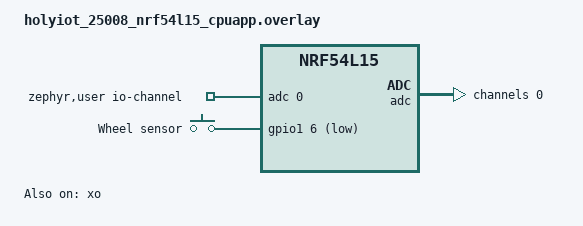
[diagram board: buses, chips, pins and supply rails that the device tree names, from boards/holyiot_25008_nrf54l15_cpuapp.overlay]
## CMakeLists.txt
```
# SPDX-License-Identifier: Apache-2.0

cmake_minimum_required(VERSION 3.20.0)

# Application-specific Kconfig options (CSC service, wheel simulation).
set(KCONFIG_ROOT ${CMAKE_CURRENT_SOURCE_DIR}/Kconfig)

find_package(Zephyr REQUIRED HINTS $ENV{ZEPHYR_BASE})
project(speed_meter)

target_sources(app PRIVATE
	src/main.c
	src/csc.c
	src/bt.c
	src/led_sw_blink.c
)

# Wheel configuration (circumference, ODR, range, detector thresholds) with
# persistence in NVS. Used by every wheel source and by the diagnostics shell.
target_sources(app PRIVATE src/wheel_config.c)

# CSCS wire state: the event-time clock and the cumulative revolution counter.
# Free of Zephyr dependencies so it can be unit-tested on the host.
target_sources(app PRIVATE src/wheel_csc.c)

# Fail-closed gate for sensor reconfiguration. Same reasoning.
target_sources(app PRIVATE src/wheel_reconfig.c)

# CR2032 measurement through the SAADC internal VDD input + Battery Service.
target_sources_ifdef(CONFIG_CSC_BATTERY app PRIVATE src/battery.c)

# Wheel revolution sources - `choice CSC_WHEEL_SOURCE` builds exactly one.
target_sources_ifdef(CONFIG_CSC_SIMULATE app PRIVATE src/wheel_source_sim.c)
target_sources_ifdef(CONFIG_CSC_WHEEL_SENSOR_GPIO app PRIVATE src/wheel_source_gpio.c)
target_sources_ifdef(CONFIG_CSC_WHEEL_SENSOR_ACCEL app PRIVATE src/wheel_source_accel.c)

# Self-calibrating revolution detector (accelerometer source and/or recorder).
target_sources_ifdef(CONFIG_CSC_WHEEL_DETECTOR app PRIVATE src/wheel_detector.c)

# Remote diagnostics (recording + calibration over the MCUmgr/SMP shell).
target_sources_ifdef(CONFIG_CSC_DIAG app PRIVATE src/wheel_diag.c)

# Low-power management (sleep on wheel standstill, wake on motion).
target_sources_ifdef(CONFIG_CSC_POWER_SAVE app PRIVATE src/wheel_power.c)

# On-demand firmware update (DFU) over BLE SMP.
target_sources_ifdef(CONFIG_CSC_DFU app PRIVATE src/dfu_mode.c)
target_sources_ifdef(CONFIG_CSC_DFU app PRIVATE src/dfu_button.c)

# Boot self-test and firmware confirmation (MCUboot).
target_sources_ifdef(CONFIG_BOOTLOADER_MCUBOOT app PRIVATE src/boot.c)
```

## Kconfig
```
# SPDX-License-Identifier: Apache-2.0

menu "Speed Meter application"

config CSC_WHEEL_REV_DATA
	bool "Wheel revolution data (speed)"
	default y
	help
	  Expose wheel revolution data: CSC Feature bit 0 and wheel fields in
	  every CSC Measurement notification. Required for speed readings.

config CSC_CRANK_REV_DATA
	bool "Crank revolution data (cadence)"
	default n
	help
	  Expose crank revolution data: CSC Feature bit 1 and crank fields in
	  every CSC Measurement notification.

config CSC_SENSOR_LOCATION
	int "Sensor Location characteristic value (0x2A5D)"
	default 9
	range 0 14
	help
	  Sensor location as defined by the Bluetooth SIG:
	  0=Other, 1=Top of shoe, 2=In shoe, 3=Hip, 4=Front wheel,
	  5=Left crank, 6=Right crank, 7=Left pedal, 8=Right pedal,
	  9=Front hub, 10=Rear dropout, 11=Chainstay, 12=Rear wheel,
	  13=Rear hub, 14=Chest.

config CSC_SC_CONTROL_POINT
	bool "SC Control Point characteristic (calibration, sensor location)"
	default n
	help
	  Expose the optional SC Control Point (0x2A55) with SET CUMULATIVE
	  VALUE, UPDATE SENSOR LOCATION and REQUEST SUPPORTED SENSOR
	  LOCATIONS opcodes (CSCS v1.0). Ported from the upstream
	  peripheral_csc sample - see reference/README.md.

config CSC_BATTERY
	bool "CR2032 voltage measurement through the SAADC VDD input"
	default y
	depends on ADC
	help
	  Measure the coin cell through the nRF54L15 SAADC's internal VDD input:
	  no divider, no extra pin, nothing to solder (the channel lives in the
	  board overlay as the first io-channel of the zephyr,user node).

	  The voltage is published as a percentage through the standard BLE
	  Battery Service. Turn this off to fall back to the fixed
	  CSC_BAS_LEVEL instead, e.g. when the board is powered from a bench
	  supply.

config CSC_BATTERY_INTERVAL_RIDING_S
	int "Battery measurement interval while riding (seconds)"
	default 300
	range 10 3600
	depends on CSC_BATTERY
	help
	  A coin cell sags under load, so the level is sampled more often while
	  the wheel is turning and the radio is busy.

config CSC_BATTERY_INTERVAL_IDLE_S
	int "Battery measurement interval while parked (seconds)"
	default 3600
	range 60 86400
	depends on CSC_BATTERY
	help
	  Relaxed cadence for a device sitting still; the measurement itself is
	  what costs power, not the timer.

config CSC_BATTERY_CAL_PPM
	int "Battery voltage calibration (parts per million)"
	default 0
	range -200000 200000
	depends on CSC_BATTERY
	help
	  Single trim factor for the measured voltage. The SAADC is accurate but
	  not exact, so compare the reported millivolts against a multimeter and
	  set the relative error here: -30000 corrects a reading that is 3% too
	  high. Watch out that a J-Link supplying the board makes the SAADC
	  measure the debugger's rail, not the cell.

config CSC_BAS_LEVEL
	int "Battery level reported when measurement is off (percent)"
	default 100
	range 0 100
	depends on BT_BAS
	help
	  Fallback published by the Battery Service (0x180F) when
	  CONFIG_CSC_BATTERY is disabled. With measurement enabled this value is
	  never used - the level comes from the SAADC.

choice CSC_WHEEL_SOURCE
	prompt "Wheel revolution source"
	default CSC_SIMULATE
	depends on CSC_WHEEL_REV_DATA
	help
	  Where wheel revolution data comes from.

config CSC_SIMULATE
	bool "Simulated wheel revolutions"
	help
	  Generate fake wheel revolutions so the sensor can be paired and
	  tested with Apple Watch / a phone before the real wheel sensor
	  hardware is attached.

config CSC_WHEEL_SENSOR_GPIO
	bool "Wheel sensor on GPIO (pulse input, alias 'wheel-sensor')"
	help
	  Count wheel revolutions from a pulse input on a GPIO - e.g. a Hall
	  sensor or a magnetic pulse contact. The pin comes from the
	  'wheel-sensor' devicetree alias (see the board overlay) and must be
	  on a port with GPIOTE support - P0 or P1 on nRF54L15, P2 has none.

config CSC_WHEEL_SENSOR_ACCEL
	bool "Magnetless: revolutions from the accelerometer (LIS2DH)"
	select SENSOR
	select LIS2DH
	select CSC_WHEEL_DETECTOR
	help
	  Count wheel revolutions from the gravity rotation the accelerometer
	  sees - no magnet and no Hall sensor on the wheel. The detector is
	  self-calibrating: the rotation plane, the axis signs and the
	  sensor-to-axis distance are all derived from the data, so the board
	  may be mounted in any orientation. Add power.conf to get automatic
	  sleep on standstill and wake on movement. The sensor comes from the
	  devicetree alias 'accel0'.

endchoice

config CSC_WHEEL_DETECTOR
	bool
	help
	  Internal: build the self-calibrating revolution detector. Selected by
	  the accelerometer wheel source and by the diagnostics recorder, both
	  of which feed it. Not user selectable.

config CSC_WHEEL_SENSOR_DEBOUNCE_MS
	int "Wheel sensor debounce time in milliseconds"
	default 20
	range 1 200
	depends on CSC_WHEEL_SENSOR_GPIO

config CSC_SIM_WHEEL_RPS
	int "Simulated wheel revolutions per second"
	default 1
	range 1 20
	depends on CSC_SIMULATE

config CSC_SIMULATE_CRANK
	bool "Simulate crank revolutions"
	default y
	depends on CSC_CRANK_REV_DATA && CSC_SIMULATE
	help
	  Generate fake crank revolutions (cadence).

config CSC_SIM_CRANK_RPM
	int "Simulated crank revolutions per minute"
	default 60
	range 20 180
	depends on CSC_SIMULATE_CRANK

config CSC_SIM_TICK_MS
	int "Simulation tick period in milliseconds"
	default 100
	range 10 1000
	depends on CSC_SIMULATE

config CSC_DIAG
	bool "Remote diagnostics: accelerometer recording and calibration"
	default n
	depends on SENSOR && SHELL
	select CSC_WHEEL_DETECTOR
	help
	  Shell commands for remote measurements over MCUmgr/SMP (used by
	  tools/wheel_cal.py): wheel status, cal get/set and accelerometer
	  recording (record start/stop/info/dump). Enable together with
	  diag.conf.

config CSC_DIAG_REC_SAMPLES
	int "Wheel diagnostics recording buffer size (samples)"
	default 4096
	range 256 16384
	depends on CSC_DIAG

config CSC_POWER_SAVE
	bool "Low-power mode: sleep on wheel standstill"
	default n
	depends on SPI
	help
	  Puts the LIS2DH12 into a 1 Hz low-power mode with a movement interrupt
	  armed on the selected INT line whenever the wheel stops, and stops the
	  BLE links and the advertising once the ride is over.

	  There is no System OFF tier: waking from it needs GPIO DETECT on P0/P1,
	  and this board's accelerometer interrupts sit on port P2, which has no
	  gpiote instance. wheel_power.c explains it at the point of use.

choice CSC_POWER_WAKE_INT
	prompt "Interrupt line the sensor arms on standstill"
	default CSC_POWER_WAKE_INT1
	depends on CSC_POWER_SAVE
	help
	  Which INT pin the LIS2DH12 routes its movement interrupt to while
	  standing still. On HOLYIOT-25008 nothing on the SoC reads either line -
	  both are on port P2, which has no GPIOTE - so this only sets what the
	  sensor does, and the 1 Hz poll is what actually notices movement.
	  Kept because it is what a board with a readable line would need.

config CSC_POWER_WAKE_INT1
	bool "INT1"

config CSC_POWER_WAKE_INT2
	bool "INT2"

endchoice

config CSC_POWER_IDLE_TIMEOUT_S
	int "Standstill timeout before sleeping (seconds)"
	default 10
	range 2 300
	depends on CSC_POWER_SAVE
	help
	  Tier 2 of the power state machine: after this long without a wheel
	  revolution the sensor alone drops to 1 Hz with a movement interrupt.
	  The BLE link is kept - stopping at a traffic light must not cost the
	  rider their connection - and the CPU stays idle between connection
	  events, which is where the saving is.

config CSC_POWER_DEEP_SLEEP_TIMEOUT_S
	int "Standstill timeout before the ride is considered over (seconds)"
	default 300
	range 30 3600
	depends on CSC_POWER_SAVE
	help
	  Tier 3: after this long without a revolution the ride is over. The BLE
	  links are dropped, the advertising stops, and the device settles into
	  System ON Idle. The first wheel movement brings everything back - the
	  sampling thread polls once a second and is its own wake source.

	  It must stay well above the traffic-light scale - the default of 5
	  minutes is the behaviour of the commercial speed sensors.

config CSC_POWER_WAKE_THS
	int "Wake threshold (INTx_THS, in +/-2g digits)"
	default 16
	range 1 127
	depends on CSC_POWER_SAVE
	help
	  Each digit is 16 mg at the standby full scale (+/-2 g). 16 digits means
	  a ~256 mg movement wakes the device.

config CSC_DFU
	bool "On-demand firmware update (DFU) over BLE"
	default n
	depends on MCUMGR_TRANSPORT_BT_DYNAMIC_SVC_REGISTRATION && MCUMGR_GRP_IMG
	help
	  Hides the MCUmgr/SMP service until dfu_mode_enter() is called (e.g. by
	  a long button press). The device then advertises as "Wheel DFU" and a
	  phone uploads a signed image to the second slot; MCUboot installs it on
	  the next reboot. Enable together with dfu.conf.

config CSC_DFU_BUTTON_LONG_MS
	int "DFU button hold duration (milliseconds)"
	default 5000
	range 1000 10000
	depends on CSC_DFU

endmenu

source "Kconfig.zephyr"
```

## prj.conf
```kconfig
# SPDX-License-Identifier: Apache-2.0
#
# Speed Meter - Bluetooth cycling speed sensor (CSCS).

# --- Bluetooth: peripheral with the Cycling Speed and Cadence service --------
CONFIG_BT=y
CONFIG_BT_PERIPHERAL=y
CONFIG_BT_DEVICE_NAME="Speed Meter"
# "Cycling: General" style appearance used by cycling sensors.
CONFIG_BT_DEVICE_APPEARANCE=1157

# Two simultaneous centrals: the Apple Watch plus a bike computer / phone
# display, both subscribed to CSC Measurement at the same time. The service
# is only advertised while fewer than BT_MAX_CONN links are up (see bt.c).
CONFIG_BT_MAX_CONN=2
CONFIG_BT_MAX_PAIRED=2
# Both Apple clients keep their own bond, and reconnecting relies on them.
CONFIG_BT_SMP=y
CONFIG_BT_SETTINGS=y

# --- Persistent configuration ------------------------------------------------
# Settings + NVS on the RRAM "storage" partition (0x174000, 36 kB):
#   - Bluetooth bonds (BT_SETTINGS) so paired watch/display reconnect after a
#     reboot or a battery change without re-pairing,
#   - wheel configuration (circumference, ODR, range, detector thresholds),
#     see src/wheel_config.c.
#
# FLASH is off by default unless MCUboot is part of the build, so ask for the
# Nordic RRAM driver explicitly; SETTINGS_NVS additionally needs FLASH_MAP.
CONFIG_FLASH=y
CONFIG_FLASH_MAP=y
CONFIG_NVS=y
CONFIG_SETTINGS=y
CONFIG_SETTINGS_NVS=y

# The CSCS service UUID (0x1816) is put in the advertising data by
# src/main.c - that is what Apple Watch scans for.

# Battery Service and Device Information Service (nice for Apple clients).
# The level comes from the SAADC; see the battery section below.
CONFIG_BT_BAS=y
CONFIG_BT_DIS=y
CONFIG_BT_DIS_PNP=n

# --- CR2032 measurement (SAADC internal VDD input) ---------------------------
# The CR2032 feeds VDD, so the SAADC can measure it internally: no divider, no
# extra pin, nothing to solder. The channel is configured in the board overlay
# as the first io-channel of the zephyr,user node - check it before changing
# anything here. CONFIG_CSC_BATTERY (Kconfig) controls the module itself.
CONFIG_ADC=y

# --- Logging -----------------------------------------------------------------
CONFIG_LOG=y
CONFIG_LOG_DEFAULT_LEVEL=3

# --- LED (Zephyr LED driver over the board's gpio-leds node) -----------------
CONFIG_LED=y

# --- Console over J-Link RTT -------------------------------------------------
# UART (P1.04 TX / P1.05 RX) is repurposed: P1.05 carries the LIS2DH12 INT1
# wake line. Keep the UART console off and log over RTT instead.
CONFIG_UART_CONSOLE=n
CONFIG_LOG_BACKEND_UART=n
CONFIG_RTT_CONSOLE=y
CONFIG_USE_SEGGER_RTT=y
CONFIG_LOG_BACKEND_RTT=y
CONFIG_LOG_BACKEND_RTT_MODE_DROP=y
```

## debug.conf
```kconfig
# SPDX-License-Identifier: Apache-2.0
#
# Extra configuration for bench debugging.
#
# NOTE: logging over J-Link RTT and the disabled UART console are now part of
# prj.conf (they apply to every build). This file is kept for build-command
# compatibility only - add any debug-only settings here.
```

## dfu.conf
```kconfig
# SPDX-License-Identifier: Apache-2.0
#
# On-demand firmware update (DFU) over BLE SMP via MCUboot.
#
# Usage (sysbuild builds MCUboot + app and merges them):
#   west build --sysbuild -b holyiot_25008/nrf54l15/cpuapp . -- \
#       -DEXTRA_CONF_FILE="debug.conf;diag.conf;power.conf;dfu.conf"
#
# The signed image to upload from nRF Connect Device Manager is:
#   build/speed_meter_diag_power_mcuboot/app/zephyr/zephyr.signed.bin

# Application-side DFU support (dfu_mode.c + dfu_button.c).
CONFIG_CSC_DFU=y

# MCUboot image management (upload + confirm + reset).
CONFIG_BOOTLOADER_MCUBOOT=y
CONFIG_FLASH=y
CONFIG_FLASH_MAP=y
CONFIG_STREAM_FLASH=y
CONFIG_IMG_MANAGER=y

# MCUmgr image-management group (in addition to the OS/shell groups from
# diag.conf).
CONFIG_MCUMGR_GRP_IMG=y

# Enable MCUmgr notification hooks (img_mgmt callbacks drive the DFU LED
# states: upload in progress / image received).
CONFIG_MCUMGR_MGMT_NOTIFICATION_HOOKS=y

# Security: pairing/encryption for the SMP service.
CONFIG_BT_SMP=y
CONFIG_BT_GATT_DYNAMIC_DB=y

# Register the SMP service on demand only (hidden until DFU mode is entered).
CONFIG_MCUMGR_TRANSPORT_BT_DYNAMIC_SVC_REGISTRATION=y
CONFIG_MCUMGR_TRANSPORT_BT_CONN_PARAM_CONTROL=y

# Require an encrypted link (overrides the plain bench permission from
# diag.conf - the DFU build is production, the bench tool uses its own build).
CONFIG_MCUMGR_TRANSPORT_BT_PERM_RW=n
CONFIG_MCUMGR_TRANSPORT_BT_PERM_RW_ENCRYPT=y

# Faster transfers.
CONFIG_BT_L2CAP_TX_MTU=498
CONFIG_BT_BUF_ACL_RX_SIZE=502
CONFIG_BT_BUF_ACL_TX_SIZE=502
CONFIG_BT_CTLR_DATA_LENGTH_MAX=251

CONFIG_MCUMGR_TRANSPORT_BT_REASSEMBLY=y
CONFIG_MCUMGR_TRANSPORT_NETBUF_SIZE=2475
CONFIG_MCUMGR_TRANSPORT_WORKQUEUE_STACK_SIZE=4608
```

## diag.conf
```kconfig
# SPDX-License-Identifier: Apache-2.0
#
# Extra configuration for the remote diagnostics build: accelerometer
# recording + calibration over MCUmgr/SMP (used by tools/wheel_cal.py).
#
# Usage:
#   west build -b holyiot_25008/nrf54l15/cpuapp . -- \
#       -DEXTRA_CONF_FILE="debug.conf;diag.conf"

# --- wheel diagnostics module ------------------------------------------------
CONFIG_SENSOR=y
CONFIG_LIS2DH=y
CONFIG_CSC_DIAG=y
CONFIG_CSC_DIAG_REC_SAMPLES=4096

# --- shell over MCUmgr (no UART console needed) ------------------------------
CONFIG_SHELL=y
CONFIG_SHELL_BACKEND_DUMMY=y
CONFIG_SHELL_BACKEND_DUMMY_BUF_SIZE=2048

CONFIG_MCUMGR=y
# MCUmgr dependencies (bez nich CONFIG_MCUMGR cicho spada do =n!).
CONFIG_NET_BUF=y
CONFIG_ZCBOR=y
CONFIG_CRC=y
CONFIG_MCUMGR_GRP_OS=y
CONFIG_MCUMGR_GRP_SHELL=y
CONFIG_MCUMGR_TRANSPORT_BT=y
# smpmgr on macOS cannot do Secure Connections pairing -> plain RW (bench only!)
CONFIG_MCUMGR_TRANSPORT_BT_PERM_RW=y
CONFIG_MCUMGR_TRANSPORT_BT_REASSEMBLY=y
CONFIG_MCUMGR_TRANSPORT_NETBUF_SIZE=2475
CONFIG_MCUMGR_TRANSPORT_WORKQUEUE_STACK_SIZE=3072
```

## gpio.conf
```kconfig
# SPDX-License-Identifier: Apache-2.0
#
# Wheel revolutions from a GPIO pulse input (Hall sensor, reed contact or any
# switch to GND) instead of the accelerometer - see src/wheel_source_gpio.c.
# The pin comes from the `wheel-sensor` devicetree alias.
#
# Usage:
#   west build -b holyiot_25008/nrf54l15/cpuapp . -- \
#       -DEXTRA_CONF_FILE="debug.conf;gpio.conf"

CONFIG_CSC_SIMULATE=n
CONFIG_CSC_WHEEL_SENSOR_GPIO=y
```

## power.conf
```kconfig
# SPDX-License-Identifier: Apache-2.0
#
# Production power configuration. Wheel revolutions come from the accelerometer
# (magnetless) and the LIS2DH12 drops to a 1 Hz standby whenever the wheel
# stops.
#
# Usage:
#   west build --sysbuild -b holyiot_25008/nrf54l15/cpuapp . -- \
#       -DEXTRA_CONF_FILE="debug.conf;diag.conf;power.conf;dfu.conf"

# --- Wheel source: accelerometer, not the simulator ---------------------------
CONFIG_CSC_SIMULATE=n
CONFIG_CSC_WHEEL_SENSOR_ACCEL=y

# --- Standstill policy: three tiers, and no System OFF ------------------------
#
#   tier 2 (10 s)   the sensor alone drops to 1 Hz and the BLE link stays up -
#                   stopping at a traffic light must not cost the rider the
#                   watch connection.
#   tier 3 (300 s)  the ride is over: links dropped, advertising stopped, and
#                   the device settles into System ON Idle. The 1 Hz wheel poll
#                   is its own wake source, so the wheel still starts the
#                   device by itself with nothing pressed.
#
# There is no System OFF tier. That is not an oversight and not a TODO.
# Waking from System OFF is GPIO DETECT on P0/P1, or RESET - this part has no
# timer wake to fall back on - and the module wires the accelerometer's INT1
# and INT2 to P2.00 and P2.03, on a port that carries no gpiote-instance in the
# SoC devicetree (gpiote30 belongs to gpio0, gpiote20 to gpio1). An unmodified
# board therefore has no wake source at all, and arming one would power the
# device down and never bring it back. The board cannot usefully be modified.
#
# The cost is battery life, not function, and it is smaller than it sounds:
# advertising every 100 ms plus a maintained link runs to tens of microamps,
# while the core idling between two 1 Hz polls costs a few. Whether that gap is
# worth buying back is a measurement question, not an argument - section 8 of
# TEST-PLAN.md specifies it, and nothing has been measured yet.
CONFIG_CSC_POWER_SAVE=y
```

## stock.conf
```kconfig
# SPDX-License-Identifier: Apache-2.0
#
# Production variant for an UNMODIFIED HOLYIOT-25008: nothing soldered, nothing
# rewired. Flash this if you have not touched the board.
#
# What works: the magnetless accelerometer source, the revolution detector, the
# CSCS service, and the full three-tier power state machine - tier 2 drops the
# sensor to 1 Hz while keeping the BLE link, tier 3 stops the links and the
# advertising altogether.
#
# What cannot work: System OFF, and the difference matters. Waking from System
# OFF on nRF54L15 is GPIO DETECT on P0/P1, or RESET - there is no timer wake to
# fall back on. The module wires INT1 to P2.00, and port 2 has neither GPIOTE
# nor SENSE, so a board that has not been modified has no way to wake the SoC.
# Arming a wake pin that is not connected would power the device down for good,
# so this variant does not arm one - and Kconfig refuses the option without
# CSC_POWER_WAKE_LINE_WIRED.
#
# Tier 3 therefore sleeps the radio instead of the chip. The device stays in
# **System ON Idle**: the links are dropped, the advertising stops, the sensor
# runs at 1 Hz, and the CPU stops in WFI between the once-a-second polls while
# everything else - RAM, LFCLK, the GRTC - keeps running. The sampling thread is
# what notices the wheel turning again and restarts advertising, so the wheel
# still starts the device by itself.
#
# System ON Idle is a description, not a switch that gets turned on. On
# nRF54L15 it is what arch_cpu_idle() does - __WFI() - and the only knob nearby
# is CONFIG_SOC_NRF_FORCE_CONSTLAT, left off because it trades power for wake
# latency.
#
# CONFIG_PM is a dead end here. This SoC selects no HAS_PM and implements no
# pm_state_set() - only nrf54h and nrf92 do - so CONFIG_PM=y does not take:
# Kconfig reports that PM "was assigned the value 'y' but got the value 'n'",
# the build still succeeds with exit 0, and the resulting .config has PM=n.
# Nothing breaks, and nothing happens either.
#
# The cost is battery life, not function, and it is smaller than it sounds:
# advertising every 100 ms plus a maintained link runs to tens of microamps,
# while the core idling between two 1 Hz polls costs a few. For the last
# microamp you need the wire, and then you want power.conf instead.
#
# Usage:
#   west build --sysbuild -b holyiot_25008/nrf54l15/cpuapp . -- \
#       -DEXTRA_CONF_FILE="debug.conf;diag.conf;stock.conf;dfu.conf"

# --- Wheel source: accelerometer, not the simulator ---------------------------
CONFIG_CSC_SIMULATE=n
CONFIG_CSC_WHEEL_SENSOR_ACCEL=y

# --- Sleep on standstill, but never power the SoC down ------------------------
# Tier 2 only. CSC_POWER_SYSTEM_OFF is deliberately absent and
# CSC_POWER_WAKE_LINE_WIRED is deliberately not set - see the header.
CONFIG_CSC_POWER_SAVE=y
```

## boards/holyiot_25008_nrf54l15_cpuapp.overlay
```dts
/*
 * Copyright (c) 2026 Mateusz Żerebecki
 *
 * SPDX-License-Identifier: Apache-2.0
 *
 * HOLYIOT-25008 (nRF54L15) bring-up overlay.
 */

#include <zephyr/dt-bindings/gpio/gpio.h>
#include <zephyr/dt-bindings/input/input-event-codes.h>
#include <zephyr/dt-bindings/adc/adc.h>
#include <zephyr/dt-bindings/adc/nrf-saadc.h>

/* Bluetooth on nRF54L15 needs both the high- and low-frequency clocks. */
&xo {
        status = "okay";
};

&lfclk {
        status = "okay";
};

/*
 * Battery measurement: the CR2032 feeds VDD, and the nRF54L15 SAADC can route
 * VDD to a channel internally - no divider, no extra pin, no soldering.
 *
 * On nRF54L15 this works through PSELP.CONNECT = Internal with
 * PSELP.INTERNAL = Vdd (NOT the nRF52-style PSELP.PSELP = VDD encoding), but
 * the devicetree-facing value is the same NRF_SAADC_VDD and the driver asserts
 * that the two definitions agree.
 *
 * Gain 1/4 keeps a fresh cell in range: the internal reference is 0.9 V, so the
 * full scale is 0.9 / (1/4) = 3.6 V. With gain 1 the 3.0-3.3 V of a fresh
 * CR2032 would sit far above the 0.9 V full scale and read as saturated.
 */
&adc {
        status = "okay";

        #address-cells = <1>;
        #size-cells = <0>;

        channel@0 {
                reg = <0>;

                zephyr,gain = "ADC_GAIN_1_4";
                zephyr,reference = "ADC_REF_INTERNAL";
                zephyr,acquisition-time = <ADC_ACQ_TIME_DEFAULT>;
                zephyr,input-positive = <NRF_SAADC_VDD>;
                zephyr,resolution = <12>;
                /* 2^4 = 16 hardware averages per sample: a battery reading
                 * does not need speed, only a quiet number. */
                zephyr,oversampling = <4>;
        };
};

/ {
        zephyr,user {
                /* Channel 0 above is the battery. */
                io-channels = <&adc 0>;
        };
};

/* UART (P1.04 TX / P1.05 RX) is not used: P1.05 is repurposed as the LIS2DH12
 * INT1 wake line (see the board overlay irq-gpios). Disable uart20 so the
 * UARTE driver never touches P1.04/P1.05. */
&uart20 {
	status = "disabled";
};

/ {
	aliases {
		/* Wheel pulse input for CONFIG_CSC_WHEEL_SENSOR_GPIO
		 * (Hall sensor / magnetic pulse contact). Default pad: P1.06 -
		 * change it to the pad you actually wired. Must be a
		 * GPIOTE-capable port: P0 or P1 on nRF54L15 (P2 has no
		 * GPIOTE!).
		 */
		wheel-sensor = &wheel_sensor;
	};

	/*
	 * The wheel pulse input is described as a gpio-keys child: only a
	 * node covered by a binding that declares the 'gpios' property gets
	 * the devicetree macros (DT_N_..._P_gpios_...) needed by
	 * GPIO_DT_SPEC_GET(). The input subsystem itself is not used - the
	 * wheel_sensor module counts revolutions through its own interrupt.
	 */
	wheel_input: wheel-input {
		compatible = "gpio-keys";

		wheel_sensor: wheel-sensor {
			/* Switch/sensor between this pin and GND; the SoC
			 * pull-up keeps the line high while the contact is
			 * open.
			 */
			gpios = <&gpio1 6 (GPIO_PULL_UP | GPIO_ACTIVE_LOW)>;
			label = "Wheel sensor";
			zephyr,code = <INPUT_KEY_0>;
		};
	};
};
```

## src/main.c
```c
/*
 * Copyright (c) 2026 Mateusz Żerebecki
 *
 * SPDX-License-Identifier: Apache-2.0
 *
 * Speed Meter - Bluetooth cycling speed sensor (CSCS, service UUID 0x1816).
 *
 * Apple Watch (watchOS 10+) and iPhone discover cycling sensors by the CSCS
 * UUID in the advertising data. This skeleton advertises the service and
 * optionally simulates wheel revolutions so it can be paired and tested
 * before the real wheel sensor hardware is attached.
 */

#include <errno.h>

#include <zephyr/kernel.h>
#include <zephyr/bluetooth/bluetooth.h>
#include <zephyr/bluetooth/services/bas.h>
#include <zephyr/logging/log.h>
#include <zephyr/settings/settings.h>

#include "bt.h"
#include "csc.h"
#include "wheel_config.h"

#if IS_ENABLED(CONFIG_CSC_BATTERY)
#include "battery.h"
#endif

#if IS_ENABLED(CONFIG_CSC_WHEEL_SENSOR_GPIO)
#include "wheel_source_gpio.h"
#endif

#if IS_ENABLED(CONFIG_CSC_WHEEL_SENSOR_ACCEL)
#include "wheel_source_accel.h"
#endif

#if IS_ENABLED(CONFIG_CSC_DFU)
#include "dfu_mode.h"
#include "dfu_button.h"
#endif

#if IS_ENABLED(CONFIG_BOOTLOADER_MCUBOOT)
#include "boot.h"
#endif

LOG_MODULE_REGISTER(main, LOG_LEVEL_INF);

/*
 * The Bluetooth advertising, status LED, boot confirmation and simulation
 * now live in their own modules: bt.c, boot.c and sim.c.
 */

int main(void)
{
	int err;

	LOG_INF("Speed Meter (CSCS, 0x1816) starting");

	/*
	 * Wheel configuration first: it seeds the defaults and registers the
	 * settings handler, so the settings_load() below also restores the wheel
	 * circumference and detector tuning.
	 */
	err = wheel_config_init();
	if (err != 0) {
		LOG_ERR("Wheel config init failed: %d", err);
	}

	err = bt_enable(NULL);
	if (err != 0) {
		LOG_ERR("Bluetooth init failed: %d", err);
		return 0;
	}

#if IS_ENABLED(CONFIG_SETTINGS)
	/*
	 * Restores the identities/bonds stored over BT_SETTINGS plus the wheel
	 * configuration. With CONFIG_BT_SETTINGS the stack has no identity
	 * address until this runs, so paired clients could not reconnect.
	 */
	err = settings_load();
	if (err != 0) {
		LOG_ERR("settings_load failed: %d", err);
	}
#endif

	(void)bt_init();

#if IS_ENABLED(CONFIG_BT_BAS)
	if (!IS_ENABLED(CONFIG_CSC_BATTERY)) {
		/*
		 * No measurement path: publish the fixed fallback level so the
		 * Battery Service still reports something sensible. With
		 * CONFIG_CSC_BATTERY the SAADC reading takes over below.
		 */
		bt_bas_set_battery_level(CONFIG_CSC_BAS_LEVEL);
	}
#endif

#if IS_ENABLED(CONFIG_CSC_BATTERY)
	/*
	 * Needs the Bluetooth stack up (it publishes through the Battery
	 * Service). Runs before advertising starts, so the first client to
	 * connect already reads a real level instead of a placeholder.
	 */
	err = battery_init();
	if (err != 0) {
		LOG_ERR("Battery measurement init failed: %d", err);
	}
#endif

	LOG_INF("Bluetooth initialized, advertising as \"%s\"", CONFIG_BT_DEVICE_NAME);
	bt_start_advertising();

#if IS_ENABLED(CONFIG_CSC_DFU)
	err = dfu_mode_init();
	if (err != 0) {
		LOG_ERR("DFU mode init failed: %d", err);
		return 0;
	}

	err = dfu_button_init();
	if (err != 0) {
		LOG_ERR("DFU button init failed: %d", err);
	}
#endif /* CONFIG_CSC_DFU */

#if IS_ENABLED(CONFIG_BOOTLOADER_MCUBOOT)
	boot_init();
#endif

#if IS_ENABLED(CONFIG_CSC_WHEEL_SENSOR_ACCEL)
	/*
	 * Magnetless source: its own thread samples the accelerometer, counts
	 * revolutions and drives the sleep/wake state machine.
	 */
	err = wheel_source_accel_init();
	if (err != 0) {
		LOG_ERR("Accelerometer wheel source init failed: %d", err);
	}
#endif /* CONFIG_CSC_WHEEL_SENSOR_ACCEL */

#if IS_ENABLED(CONFIG_CSC_WHEEL_SENSOR_GPIO)
	err = wheel_source_gpio_init();
	if (err != 0) {
		LOG_ERR("Wheel sensor init failed: %d", err);
	}

	LOG_INF("Wheel source: GPIO wheel sensor - waiting for revolutions");

	for (;;) {
		struct wheel_revolution_data wheel;

		k_sleep(K_SECONDS(1));
		wheel_source_gpio_read(&wheel);
		if (wheel.has_new_revolution) {
			LOG_INF("Wheel revolution %u (t=%u)", wheel.revolutions,
				wheel.last_event_time);
			csc_publish_wheel(wheel.revolutions, wheel.last_event_time);
		}
	}
#endif /* CONFIG_CSC_WHEEL_SENSOR_GPIO */

	return 0;
}
```

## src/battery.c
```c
/*
 * Copyright (c) 2026 Mateusz Żerebecki
 *
 * SPDX-License-Identifier: Apache-2.0
 *
 * CR2032 battery measurement - see battery.h.
 *
 * Zephyr provides the whole measurement path (SAADC driver, devicetree
 * channel, raw-to-millivolts conversion). The one thing it does not provide is
 * a voltage-to-percentage curve for a coin cell, because that depends on the
 * cell chemistry and the load profile - so the curve below is ours, and the
 * absolute accuracy can be trimmed against a multimeter with
 * CONFIG_CSC_BATTERY_CAL_PPM.
 */

#include "battery.h"

#include <errno.h>

#include <zephyr/bluetooth/services/bas.h>
#include <zephyr/device.h>
#include <zephyr/devicetree.h>
#include <zephyr/drivers/adc.h>
#include <zephyr/kernel.h>
#include <zephyr/logging/log.h>
#include <zephyr/sys/util.h>

#if IS_ENABLED(CONFIG_CSC_POWER_SAVE)
#include "wheel_power.h"
#endif

LOG_MODULE_REGISTER(battery, LOG_LEVEL_INF);

#define BATTERY_NODE DT_PATH(zephyr_user)

#if !DT_NODE_EXISTS(BATTERY_NODE)
#error "CONFIG_CSC_BATTERY needs the zephyr,user node with io-channels (see the board overlay)."
#endif

static const struct adc_dt_spec battery_adc =
	ADC_DT_SPEC_GET_BY_IDX(BATTERY_NODE, 0);

static struct k_work_delayable battery_work;

static uint8_t last_percent;
static bool adc_ready;

/* Offset calibration only has to run once after reset. */
static bool adc_calibrated;

/*
 * CR2032 discharge curve, no-load and at a low duty cycle. Interpolated rather
 * than scaled, because a coin cell holds a plateau around 2.9-3.0 V and then
 * falls off quickly.
 */
struct battery_point {
	uint16_t mv;
	uint8_t percent;
};

static const struct battery_point cr2032_curve[] = {
	{ 3200, 100 },
	{ 3050, 95 },
	{ 3000, 90 },
	{ 2950, 80 },
	{ 2900, 65 },
	{ 2850, 50 },
	{ 2800, 35 },
	{ 2700, 18 },
	{ 2600, 7 },
	{ 2500, 0 },
};

static bool standby(void)
{
#if IS_ENABLED(CONFIG_CSC_POWER_SAVE)
	/* wheel_power only leaves standby when the wheel is turning. */
	return wheel_power_is_standby();
#else
	return false;
#endif
}

static void schedule_next(void)
{
	uint32_t interval_s = standby() ? CONFIG_CSC_BATTERY_INTERVAL_IDLE_S
					: CONFIG_CSC_BATTERY_INTERVAL_RIDING_S;

	(void)k_work_reschedule(&battery_work, K_SECONDS(interval_s));
}

static void battery_work_handler(struct k_work *work)
{
	ARG_UNUSED(work);

	(void)battery_update();
	schedule_next();
}

int battery_read_mv(int32_t *voltage_mv)
{
	int16_t raw;
	int err;
	struct adc_sequence sequence = {
		.buffer = &raw,
		.buffer_size = sizeof(raw),
	};

	if (!adc_ready) {
		return -ENODEV;
	}

	err = adc_sequence_init_dt(&battery_adc, &sequence);
	if (err != 0) {
		return err;
	}

	/* The offset calibration is only valid once per power cycle. */
	sequence.calibrate = !adc_calibrated;

	err = adc_read_dt(&battery_adc, &sequence);
	if (err != 0) {
		return err;
	}
	adc_calibrated = true;

	/*
	 * adc_raw_to_millivolts_dt() takes the raw value in *voltage_mv and
	 * converts it in place, using the gain/reference/resolution from
	 * devicetree and the driver's internal reference value.
	 */
	*voltage_mv = raw;
	err = adc_raw_to_millivolts_dt(&battery_adc, voltage_mv);
	if (err != 0) {
		return err;
	}

#if CONFIG_CSC_BATTERY_CAL_PPM != 0
	*voltage_mv = (int32_t)(((int64_t)*voltage_mv *
				 (1000000 + CONFIG_CSC_BATTERY_CAL_PPM)) /
				1000000);
#endif

	return 0;
}

uint8_t battery_percent_from_mv(int32_t voltage_mv)
{
	if (voltage_mv >= cr2032_curve[0].mv) {
		return 100U;
	}

	for (size_t i = 1; i < ARRAY_SIZE(cr2032_curve); i++) {
		const struct battery_point *high = &cr2032_curve[i - 1];
		const struct battery_point *low = &cr2032_curve[i];

		if (voltage_mv >= low->mv) {
			int32_t span_mv = high->mv - low->mv;
			int32_t span_pct = high->percent - low->percent;

			return (uint8_t)(low->percent +
					 ((voltage_mv - low->mv) * span_pct) / span_mv);
		}
	}

	return 0U;
}

int battery_update(void)
{
	int32_t mv = 0;
	int err = battery_read_mv(&mv);

	if (err != 0) {
		LOG_WRN("battery read failed: %d", err);
		return err;
	}

	last_percent = battery_percent_from_mv(mv);
	LOG_INF("battery: %d mV (%u%%)", (int)mv, last_percent);

#if IS_ENABLED(CONFIG_BT_BAS)
	bt_bas_set_battery_level(last_percent);
#endif

	return 0;
}

uint8_t battery_percent(void)
{
	return last_percent;
}

void battery_request_update(void)
{
	if (adc_ready) {
		(void)k_work_reschedule(&battery_work, K_SECONDS(1));
	}
}

int battery_init(void)
{
	int err;

	k_work_init_delayable(&battery_work, battery_work_handler);

	if (!adc_is_ready_dt(&battery_adc)) {
		LOG_ERR("SAADC not ready");
		return -ENODEV;
	}

	err = adc_channel_setup_dt(&battery_adc);
	if (err != 0) {
		LOG_ERR("ADC channel setup failed: %d", err);
		return err;
	}

	adc_ready = true;

	/* First measurement right away, so the Battery Service is never stale. */
	err = battery_update();
	if (err != 0) {
		return err;
	}

	schedule_next();
	return 0;
}
```

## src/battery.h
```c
/*
 * Copyright (c) 2026 Mateusz Żerebecki
 *
 * SPDX-License-Identifier: Apache-2.0
 *
 * CR2032 battery measurement through the nRF54L15 SAADC's internal VDD input.
 *
 * The coin cell feeds VDD directly, and the SAADC can route VDD to a channel
 * internally, so there is no divider, no extra pin and nothing to solder. See
 * the board overlay for the channel configuration (gain 1/4 against the 0.9 V
 * internal reference, i.e. a 3.6 V full scale).
 *
 * The measured voltage is published as a percentage through the standard BLE
 * Battery Service. Enable with CONFIG_CSC_BATTERY.
 */

#ifndef SPEED_METER_BATTERY_H_
#define SPEED_METER_BATTERY_H_

#include <stdbool.h>
#include <stdint.h>

/**
 * @brief Set the ADC channel up and take a first reading.
 *
 * @return 0 on success, negative errno otherwise. Failure is not fatal: the
 *         Battery Service then keeps reporting CONFIG_CSC_BAS_LEVEL.
 */
int battery_init(void);

/**
 * @brief Read the battery voltage in millivolts.
 *
 * @return 0 on success, negative errno otherwise.
 */
int battery_read_mv(int32_t *voltage_mv);

/**
 * @brief Convert a CR2032 voltage to an approximate state of charge.
 *
 * A coin cell does not discharge linearly, so this interpolates a discharge
 * curve rather than scaling the voltage.
 */
uint8_t battery_percent_from_mv(int32_t voltage_mv);

/**
 * @brief Measure and publish the level over the BLE Battery Service.
 *
 * @return 0 on success, negative errno otherwise.
 */
int battery_update(void);

/**
 * @brief Current state of charge as last published, 0 when never measured.
 */
uint8_t battery_percent(void);

/**
 * @brief Ask for a measurement soon (e.g. right after a burst of BLE traffic).
 *
 * Safe to call from any context; it only reschedules a work item.
 */
void battery_request_update(void);

#endif /* SPEED_METER_BATTERY_H_ */
```

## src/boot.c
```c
/*
 * Copyright (c) 2026 Mateusz Żerebecki
 *
 * SPDX-License-Identifier: Apache-2.0
 *
 * Boot-time self-test and firmware confirmation - see boot.h.
 */

#include "boot.h"

#include <zephyr/dfu/mcuboot.h>
#include <zephyr/drivers/led.h>
#include <zephyr/kernel.h>
#include <zephyr/logging/log.h>

#if IS_ENABLED(CONFIG_CSC_POWER_SAVE)
#include "wheel_power.h"
#endif

LOG_MODULE_REGISTER(boot, LOG_LEVEL_INF);

static const struct led_dt_spec led_red = LED_DT_SPEC_GET(DT_ALIAS(led0));
static const struct led_dt_spec led_green = LED_DT_SPEC_GET(DT_ALIAS(led1));
static const struct led_dt_spec led_blue = LED_DT_SPEC_GET(DT_ALIAS(led2));

static bool self_test_ok(void)
{
#if IS_ENABLED(CONFIG_CSC_POWER_SAVE)
	/* Minimal self-test: the LIS2DH12 answers WHO_AM_I over SPI. */
	return wheel_power_selftest();
#else
	return true;
#endif
}

static void blink(const struct led_dt_spec *spec, unsigned int times,
		  uint32_t period_ms)
{
	if (spec == NULL || times == 0U || period_ms == 0U) {
		return;
	}
	if (!led_is_ready_dt(spec)) {
		return;
	}

	(void)led_off_dt(spec);

	for (unsigned int i = 0U; i < times; i++) {
		(void)led_on_dt(spec);
		k_msleep(period_ms);
		(void)led_off_dt(spec);
		k_msleep(period_ms);
	}
}

/*
 * Alternating two-colour blink: a, b, a, b ... (pairs * 2 flashes).
 * Total duration: pairs * 2 * period_ms.
 *
 * Each colour is switched off before the next one is lit: lighting both for
 * even a moment would spike the current drawn from the coin cell and mix the
 * two colours.
 *
 * Blocking (k_msleep), so it must run from thread context - never from an ISR
 * or the system workqueue, where it would stall every other work item for the
 * whole animation. For a longer animation use led_sw_blink.c instead, which
 * toggles from a delayable work and can be cancelled - that is what the 5 s
 * DFU hold in dfu_button.c needs, since it must keep sampling the button.
 */
static void blink_alt(const struct led_dt_spec *a, const struct led_dt_spec *b,
		      unsigned int pairs, uint32_t period_ms)
{
	if (a == NULL || b == NULL || pairs == 0U || period_ms == 0U) {
		return;
	}
	if (!led_is_ready_dt(a) || !led_is_ready_dt(b)) {
		return;
	}

	(void)led_off_dt(a);
	(void)led_off_dt(b);

	for (unsigned int i = 0U; i < pairs; i++) {
		/* A */
		(void)led_off_dt(b);
		(void)led_on_dt(a);
		k_msleep(period_ms);

		/* B */
		(void)led_off_dt(a);
		(void)led_on_dt(b);
		k_msleep(period_ms);
	}

	(void)led_off_dt(a);
	(void)led_off_dt(b);
}

static void confirm_firmware(void)
{
	if (!self_test_ok()) {
		LOG_ERR("Self-test failed - image will roll back on reboot");
		blink_alt(&led_blue, &led_red, 2, 150);
		return;
	}

	if (!boot_is_img_confirmed()) {
		int err = boot_write_img_confirmed();

		if (err != 0) {
			LOG_ERR("Image confirmation failed: %d", err);
			blink_alt(&led_blue, &led_red, 2, 150);
		} else {
			LOG_INF("Firmware image confirmed");
			blink(&led_green, 3, 150);
		}
	}
}

void boot_init(void)
{
	confirm_firmware();
}
```

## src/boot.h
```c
/*
 * Copyright (c) 2026 Mateusz Żerebecki
 *
 * SPDX-License-Identifier: Apache-2.0
 *
 * Boot-time self-test and firmware confirmation (MCUboot).
 *
 * After a DFU reboot the new image is confirmed only if the self-test passes;
 * otherwise MCUboot rolls it back on the next reboot. The result is signalled
 * on the LEDs: green = confirmed, blue/red alternating = failed.
 */

#ifndef SPEED_METER_BOOT_H_
#define SPEED_METER_BOOT_H_

/** @brief Run the self-test and confirm the running image. */
void boot_init(void);

#endif /* SPEED_METER_BOOT_H_ */
```

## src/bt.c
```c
/*
 * Copyright (c) 2026 Mateusz Żerebecki
 *
 * SPDX-License-Identifier: Apache-2.0
 *
 * Bluetooth bring-up - see bt.h.
 */

#include "bt.h"

#include <errno.h>

#include <zephyr/kernel.h>
#include <zephyr/bluetooth/bluetooth.h>
#include <zephyr/bluetooth/conn.h>
#include <zephyr/bluetooth/hci.h>
#include <zephyr/bluetooth/uuid.h>
#include <zephyr/drivers/led.h>
#include <zephyr/logging/log.h>
#include <zephyr/sys/atomic.h>
#include <zephyr/sys/util.h>

#include "led_sw_blink.h"

#if IS_ENABLED(CONFIG_CSC_BATTERY)
#include "battery.h"
#endif

#if IS_ENABLED(CONFIG_MCUMGR_TRANSPORT_BT)
#include <zephyr/mgmt/mcumgr/transport/smp_bt.h>
#endif

LOG_MODULE_REGISTER(bt, LOG_LEVEL_INF);

/*
 * Advertising profile. The GAP "fast" profile (BT_LE_ADV_CONN_FAST_1) is
 * 30/60 ms, which is wasteful for a sensor that may advertise for hours when
 * nobody is around. 100/150 ms keeps discovery snappy while cutting the
 * average advertising current; the real saving is System OFF, see
 * wheel_power.c.
 */
#define BT_LE_ADV_WHEEL                                                                           \
	BT_LE_ADV_PARAM(BT_LE_ADV_OPT_CONN, BT_GAP_ADV_FAST_INT_MIN_2,                            \
			BT_GAP_ADV_FAST_INT_MAX_2, NULL)

/* Number of live links, so advertising can stop exactly at BT_MAX_CONN. */
static atomic_t conn_count;

/* Set while the device is on its way into System OFF: every advertising
 * request (including the one a disconnect would normally trigger) is ignored,
 * so a client cannot attach during the teardown window. */
static atomic_t adv_suppressed;

/* Blue LED signalling: 3 blinks on connect/pairing, fast blink while pairing. */
#define BT_LED_ON_MS  100
#define BT_LED_OFF_MS 100
#define BT_LED_BLINKS 3

static const struct led_dt_spec led_blue = LED_DT_SPEC_GET(DT_ALIAS(led2));

static struct led_sw_blink led_blue_blink;

static const struct bt_data advertising_data[] = {
	BT_DATA_BYTES(BT_DATA_FLAGS, BT_LE_AD_GENERAL | BT_LE_AD_NO_BREDR),
	/*
	 * The CSCS service UUID (0x1816) MUST be advertised - Apple Watch
	 * lists sensors found in Settings -> Bluetooth -> cycling sensors
	 * based on this UUID.
	 */
	BT_DATA_BYTES(BT_DATA_UUID16_ALL, BT_UUID_16_ENCODE(BT_UUID_CSC_VAL),
		      BT_UUID_16_ENCODE(BT_UUID_BAS_VAL)),
#if IS_ENABLED(CONFIG_MCUMGR_TRANSPORT_BT) && \
	!IS_ENABLED(CONFIG_MCUMGR_TRANSPORT_BT_DYNAMIC_SVC_REGISTRATION)
	/*
	 * MCUmgr/SMP service - remote diagnostics (tools/wheel_cal.py).
	 * With dynamic service registration the SMP service is hidden until
	 * DFU mode is entered, so it is not advertised here.
	 */
	BT_DATA_BYTES(BT_DATA_UUID128_ALL, SMP_BT_SVC_UUID_VAL),
#endif
};

static const struct bt_data scan_response_data[] = {
	BT_DATA(BT_DATA_NAME_COMPLETE, CONFIG_BT_DEVICE_NAME,
		sizeof(CONFIG_BT_DEVICE_NAME) - 1),
};

static struct k_work advertise_work;

static void advertise(struct k_work *work)
{
	ARG_UNUSED(work);

	int err;

	if (atomic_get(&adv_suppressed) != 0) {
		return;
	}

	/*
	 * Advertising is connectable, so the controller stops it by itself when
	 * a link comes up. Re-evaluate on every event: advertise while there is
	 * a free slot (so a second central can connect), stop once full.
	 */
	if (atomic_get(&conn_count) >= CONFIG_BT_MAX_CONN) {
		err = bt_le_adv_stop();
		if (err != 0 && err != -EALREADY) {
			LOG_WRN("Advertising stop failed: %d", err);
		}
		return;
	}

	err = bt_le_adv_start(BT_LE_ADV_WHEEL, advertising_data,
			      ARRAY_SIZE(advertising_data), scan_response_data,
			      ARRAY_SIZE(scan_response_data));
	if (err != 0 && err != -EALREADY) {
		LOG_ERR("Advertising failed: %d", err);
	}
}

void bt_start_advertising(void)
{
	k_work_submit(&advertise_work);
}

static void disconnect_one(struct bt_conn *conn, void *data)
{
	ARG_UNUSED(data);

	/* BT_HCI_ERR_REMOTE_USER_TERM_CONN: a clean "user asked to stop", which
	 * clients handle better than a supervision timeout. Even if it does not
	 * get out before the radio dies, the peer simply times out and
	 * reconnects on the next wake.
	 */
	(void)bt_conn_disconnect(conn, BT_HCI_ERR_REMOTE_USER_TERM_CONN);
}

void bt_prepare_sleep(void)
{
	/* Suppress first: disconnecting would otherwise re-arm advertising. */
	(void)atomic_set(&adv_suppressed, 1);
	(void)bt_le_adv_stop();
	bt_conn_foreach(BT_CONN_TYPE_LE, disconnect_one, NULL);
}

void bt_resume(void)
{
	/*
	 * The mirror image, and the reason the flag is not simply set and
	 * forgotten: on a board without a wake line the radio is what goes to
	 * sleep, and this runs again on the next revolution with no reboot in
	 * between.
	 */
	(void)atomic_set(&adv_suppressed, 0);
	bt_start_advertising();
}

/* Finite blink: N cycles via the software blinker, then off. */
static inline void bt_led_blink_n(uint32_t cycles, uint32_t on_ms, uint32_t off_ms)
{
	(void)led_sw_blink_start(&led_blue_blink, on_ms, off_ms, cycles);
}

/* Continuous blink (0 cycles = until stopped), e.g. while pairing. */
static inline void bt_led_blink_forever(uint32_t on_ms, uint32_t off_ms)
{
	(void)led_sw_blink_start(&led_blue_blink, on_ms, off_ms, 0U);
}

static inline void bt_led_off(void)
{
	led_sw_blink_stop(&led_blue_blink);
}

static void connected(struct bt_conn *conn, uint8_t err)
{
	ARG_UNUSED(conn);

	if (err != 0U) {
		LOG_WRN("Connection failed: 0x%02x %s", err, bt_hci_err_to_str(err));
		/* The slot never became usable - make sure we still advertise. */
		bt_start_advertising();
		return;
	}

	(void)atomic_inc(&conn_count);

	LOG_INF("Connected (%ld/%d)", (long)atomic_get(&conn_count),
		CONFIG_BT_MAX_CONN);
	bt_led_blink_n(BT_LED_BLINKS, BT_LED_ON_MS, BT_LED_OFF_MS);

	/*
	 * Pairing and service discovery are the heaviest radio burst the device
	 * ever runs, and a coin cell sags under that load. Re-measure shortly
	 * afterwards so the Battery Service reflects the real, loaded voltage
	 * rather than the relaxed reading taken while idle.
	 */
#if IS_ENABLED(CONFIG_CSC_BATTERY)
	battery_request_update();
#endif

	/*
	 * Keep advertising while a slot is free: this is what lets the Apple
	 * Watch and a bike computer / phone display stay connected at the same
	 * time. bt_gatt_notify(NULL, ...) feeds them all (see csc.c).
	 */
	bt_start_advertising();
}

static void disconnected(struct bt_conn *conn, uint8_t reason)
{
	ARG_UNUSED(conn);

	LOG_INF("Disconnected: 0x%02x %s", reason, bt_hci_err_to_str(reason));
	(void)atomic_dec(&conn_count);
	bt_led_off();

	/* Auto-reconnect: advertise again so the watch/display can come back. */
	bt_start_advertising();
}

#if IS_ENABLED(CONFIG_BT_SMP)
static void security_changed(struct bt_conn *conn, bt_security_t level,
			     enum bt_security_err err)
{
	ARG_UNUSED(conn);
	ARG_UNUSED(level);

	if (err != BT_SECURITY_ERR_SUCCESS) {
		LOG_WRN("Pairing failed: %d", err);
		bt_led_off();
		return;
	}

	/* Paired: quick 3-blink confirmation, then off. */
	bt_led_blink_n(BT_LED_BLINKS, BT_LED_ON_MS, BT_LED_OFF_MS);
}
#endif /* CONFIG_BT_SMP */

static void recycled(void)
{
	k_work_submit(&advertise_work);
}

BT_CONN_CB_DEFINE(conn_callbacks) = {
	.connected = connected,
	.disconnected = disconnected,
#if IS_ENABLED(CONFIG_BT_SMP)
	.security_changed = security_changed,
#endif
	.recycled = recycled,
};

#if IS_ENABLED(CONFIG_BT_SMP)
static void pairing_confirm(struct bt_conn *conn)
{
	ARG_UNUSED(conn);

	LOG_INF("Pairing requested");
	bt_led_blink_forever(BT_LED_ON_MS, BT_LED_OFF_MS);
}

static void pairing_cancel(struct bt_conn *conn)
{
	ARG_UNUSED(conn);

	LOG_INF("Pairing cancelled");
	bt_led_off();
}

static struct bt_conn_auth_cb auth_callbacks = {
	.pairing_confirm = pairing_confirm,
	.cancel = pairing_cancel,
};
#endif /* CONFIG_BT_SMP */

int bt_init(void)
{
	k_work_init(&advertise_work, advertise);
	(void)led_sw_blink_init(&led_blue_blink, &led_blue);

#if IS_ENABLED(CONFIG_BT_SMP)
	(void)bt_conn_auth_cb_register(&auth_callbacks);
#endif
	return 0;
}
```

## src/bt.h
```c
/*
 * Copyright (c) 2026 Mateusz Żerebecki
 *
 * SPDX-License-Identifier: Apache-2.0
 *
 * Bluetooth bring-up: advertising and connection/pairing callbacks.
 * Signals the connection state on the blue LED (led2) via the Zephyr LED
 * driver; every signal ends with the LED off to save battery.
 */

#ifndef SPEED_METER_BT_H_
#define SPEED_METER_BT_H_

/** @brief Prepare advertising and register pairing callbacks (after bt_enable). */
int bt_init(void);

/** @brief Start normal (CSCS) advertising. */
void bt_start_advertising(void);

/**
 * @brief Stop advertising and drop every link, ahead of System OFF.
 *
 * A wake from System OFF is a reboot, so there is nothing to preserve: the
 * client reconnects by itself once the device is back and advertising again.
 * Advertising stays suppressed until then, so nothing re-attaches during the
 * teardown window.
 */
void bt_prepare_sleep(void);

/**
 * @brief Undo bt_prepare_sleep(): advertise again.
 *
 * Needed by boards where System OFF is not used and the radio is what sleeps
 * instead - there the device comes back without a reboot, so something has to
 * lift the suppression. Until this existed the flag was a one-way door, which
 * was fine only because its single caller was followed by sys_poweroff().
 *
 * Safe to call when already advertising: bt_le_adv_start() returns -EALREADY
 * and that is handled.
 */
void bt_resume(void);

#endif /* SPEED_METER_BT_H_ */
```

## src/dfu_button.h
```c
/*
 * Copyright (c) 2026 Mateusz Żerebecki
 *
 * SPDX-License-Identifier: Apache-2.0
 *
 * DFU entry trigger: a long press of the board button (sw0, P1.13) enters
 * DFU mode via dfu_mode_enter().
 */

#ifndef SPEED_METER_DFU_BUTTON_H_
#define SPEED_METER_DFU_BUTTON_H_

/** @brief Start the long-press detection thread. */
int dfu_button_init(void);

#endif /* SPEED_METER_DFU_BUTTON_H_ */
```
